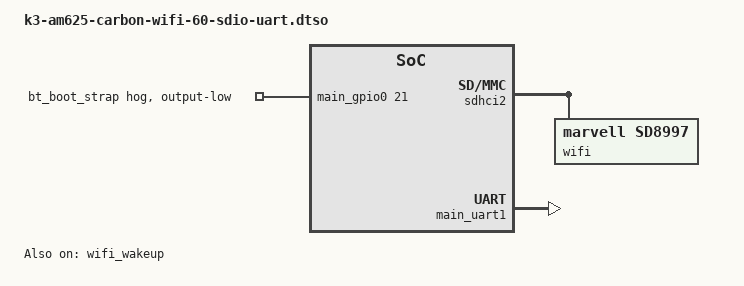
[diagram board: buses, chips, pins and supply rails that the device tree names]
// SPDX-License-Identifier: (GPL-2.0+ OR MIT)
/*
 * SDIO Summit/Sterling 60 in SDIO-UART mode
 *
 * Copyright (C) 2024 Ezurio LLC
 */

/dts-v1/;
/plugin/;

#include <dt-bindings/gpio/gpio.h>

&reg_wifi_en {
	startup-delay-us = <1000>;
	off-on-delay-us = <100000>;
};

&sdhci2 {
	status = "okay";

	wifi: wifi {
		compatible = "marvell,sd8997";
		fwtype = "sdio-uart";
	};
};

&main_uart1 {
	status = "okay";
};

&wifi_wakeup {
	status = "okay";
};

&main_gpio0 {
	bt_boot_strap: bt-boot-strap {
		gpio-hog;
		gpios = <21 GPIO_ACTIVE_HIGH>;
		output-low; // BT UART
	};
};
